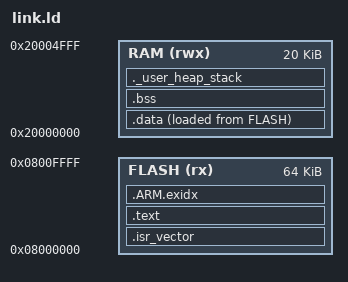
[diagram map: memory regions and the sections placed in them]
/*
 * link.ld：STM32F103C8（64 KiB Flash，20 KiB SRAM）的最小 RT-Thread 链接脚本，
 * 在 1.8 节脚本的基础上加入 .rti_fn 与 FSymTab 的收集段。
 *
 * blue-pill BSP 的 board/linker_scripts/link.lds 用 ROM/RAM 两个区名，
 * 并把 .ARM.exidx 等段也一并安排；本文件只保留编译检查需要的部分。
 */
ENTRY(Reset_Handler)

MEMORY
{
    FLASH (rx)  : ORIGIN = 0x08000000, LENGTH = 64K
    RAM   (rwx) : ORIGIN = 0x20000000, LENGTH = 20K
}

_estack = ORIGIN(RAM) + LENGTH(RAM);

SECTIONS
{
    .isr_vector :
    {
        . = ALIGN(4);
        KEEP(*(.isr_vector))
        . = ALIGN(4);
    } > FLASH

    .text :
    {
        . = ALIGN(4);
        *(.text)
        *(.text*)
        *(.rodata)
        *(.rodata*)
        *(.glue_7)
        *(.glue_7t)

        . = ALIGN(4);
        __fsymtab_start = .;
        KEEP(*(FSymTab))
        __fsymtab_end = .;

        . = ALIGN(4);
        __rt_init_start = .;
        KEEP(*(SORT(.rti_fn*)))
        __rt_init_end = .;

        . = ALIGN(4);
        _etext = .;
    } > FLASH

    .ARM.exidx :
    {
        *(.ARM.exidx*)
    } > FLASH

    _sidata = LOADADDR(.data);

    .data :
    {
        . = ALIGN(4);
        _sdata = .;
        *(.data)
        *(.data*)
        . = ALIGN(4);
        _edata = .;
    } > RAM AT> FLASH

    .bss :
    {
        . = ALIGN(4);
        _sbss = .;
        __bss_start__ = _sbss;
        *(.bss)
        *(.bss*)
        *(COMMON)
        . = ALIGN(4);
        _ebss = .;
        __bss_end__ = _ebss;
    } > RAM

    ._user_heap_stack :
    {
        . = ALIGN(8);
        PROVIDE(end = .);
        PROVIDE(__bss_end = .);
        . = . + 0x200;
        . = . + 0x400;
        . = ALIGN(8);
    } > RAM
}
